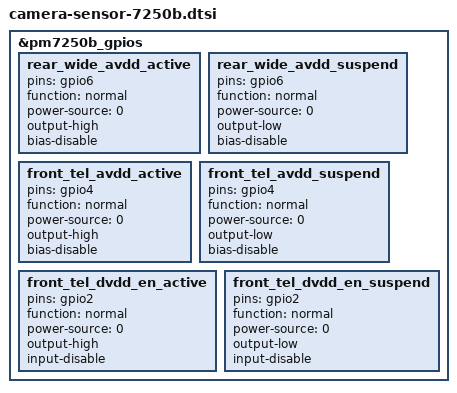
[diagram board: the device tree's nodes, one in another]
&pm7250b_gpios {
	rear_wide_avdd_active: rear_wide_avdd_active {
		pins = "gpio6";
		function = "normal";
		power-source = <0>;
		output-high;
		bias-disable;
	};

	rear_wide_avdd_suspend: rear_wide_avdd_suspend {
		pins = "gpio6";
		function = "normal";
		power-source = <0>;
		output-low;
		bias-disable;
	};

	front_tel_avdd_active: front_tel_avdd_active {
		pins = "gpio4";
		function = "normal";
		power-source = <0>;
		output-high;
		bias-disable;
	};

	front_tel_avdd_suspend: front_tel_avdd_suspend {
		pins = "gpio4";
		function = "normal";
		power-source = <0>;
		output-low;
		bias-disable;
	};

	front_tel_dvdd_en_active: front_tel_dvdd_en_active {
		pins = "gpio2";
		function = "normal";
		power-source = <0>;
		output-high;
		input-disable;
	};

	front_tel_dvdd_en_suspend: front_tel_dvdd_en_suspend {
		pins = "gpio2";
		function = "normal";
		power-source = <0>;
		output-low;
		input-disable;
	};
};
